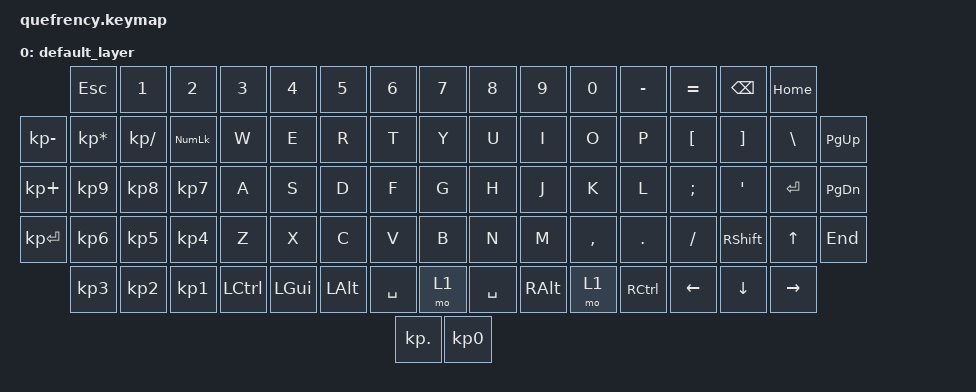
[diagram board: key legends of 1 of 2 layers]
/*
 * Copyright (c) 2020 The ZMK Contributors
 *
 * SPDX-License-Identifier: MIT
 */

#include <behaviors.dtsi>
#include <dt-bindings/zmk/bt.h>
#include <dt-bindings/zmk/keys.h>

/ {
    keymap {
        compatible = "zmk,keymap";

// ------------------------------------------------------------------------------------------------------------------------------------------
// |  NA  |  NA  | MAC1 | MAC2 | |  ESC | F1  | F2  | F3  | F4  | F5  |        | F6  | F7  | F8  | F9  | F10 | F11 | F12 | DEL |  NA |  NA  |
// | Num- | Num* | Num/ | NumL | |   ~  |  1  |  2  |  3  |  4  |  5  |        |  6  |  7  |  8  |  9  |  0  |  -  |  +  |BCKSP|  NA | HOME |
// | Num+ | Num9 | Num8 | Num7 | |  TAB |  Q  |  W  |  E  |  R  |  T  |        |  Y  |  U  |  I  |  O  |  P  |  [  |  ]  |  \  |  NA | PGUP |
// | NumE | Num6 | Num5 | Num4 | | CAPS |  A  |  S  |  D  |  F  |  G  |        |  H  |  J  |  K  |  L  |  ;  |  '  |R-ENT|  NA |  NA | PGDN |
// |  NA  | Num3 | Num2 | Num1 | |SHIFT |  Z  |  X  |  C  |  V  |  B  |        |  N  |  M  |  ,  |  .  |  /  |R-SHT|  NA |  NA | UP  |  END |
// |  NA  | Num. | Num0 |  NA  | | CTRL | WIN | ALT | SPA | MAC3| MAC4|        | SPA | MAC5| MAC6|  NA |R-ALT|R-WIN|RCTRL| LEFT| DWN | RIGHT|
// ------------------------------------------------------------------------------------------------------------------------------------------

        default_layer {
            bindings = <
                                                                                  &kp ESC   &kp N1     &kp N2   &kp N3    &kp N4 &kp N5 &kp N6 /**/     &kp N7    &kp N8   &kp N9    &kp N0    &kp MINUS &kp EQUAL &kp BSPC               &kp HOME
    &kp KP_MINUS   &kp KP_MULTIPLY &kp KP_SLASH  &kp KP_NUM                          &kp W    &kp E     &kp R  &kp T    /**/     &kp Y     &kp U    &kp I     &kp O     &kp P     &kp LBKT  &kp RBKT &kp BSLH &kp PG_UP
    &kp KP_PLUS    &kp KP_N9       &kp KP_N8     &kp KP_N7                          &kp A    &kp S    &kp D     &kp F  &kp G         /**/     &kp H     &kp J    &kp K     &kp L     &kp SEMI  &kp SQT   &kp RET                &kp PG_DN
    &kp KP_ENTER   &kp KP_N6       &kp KP_N5     &kp KP_N4                         &kp Z    &kp X    &kp C     &kp V  &kp B         /**/     &kp N     &kp M    &kp COMMA &kp DOT   &kp FSLH  &kp RSHFT &kp UP                 &kp END
                   &kp KP_N3       &kp KP_N2     &kp KP_N1                                 &kp LCTRL &kp LGUI &kp LALT &kp SPACE &mo 1                /**/     &kp SPACE &kp RALT &mo 1     &kp RCTRL &kp LEFT  &kp DOWN                         &kp RIGHT
                   &kp KP_DOT      &kp KP_N0 
            >;
        };

// ----------------------------------------------     -----------------------------------------------------
// |BT_CLR|  F1  |  F2 |  F3  |  F4 |  F5 |  F6 |     |  F7 |  F8 |  F9 | F10 | F11 | F12 |        |BT_CLR|
// |       | BT-0 | BT-1| BT-2 |     |     |       |     |     |     |     |     |     |     |     |      |
// |        |      |     |      |     |     |       |     |     |     |     |     |     |          |      |
// |         |      |     |     |      |     |       |     |     |     |     |     |         |     |      |
// |         |      |      |           |     |       |             |      |    |       |     |     |      |
// -------------------------------------------       ------------------------------------------------------

        fn_layer {
            bindings = <
    &bt BT_CLR &kp F1       &kp F2       &kp F3       &kp F4 &kp F5 &kp F6 /**/ &kp F7 &kp F8 &kp F9 &kp F10 &kp F11 &kp F12 &trans &bt BT_CLR
    &trans     &bt BT_SEL 0 &bt BT_SEL 1 &bt BT_SEL 2 &trans &trans        /**/ &trans &trans &trans &trans  &trans  &trans  &trans &trans &trans
    &trans     &trans       &trans       &trans       &trans &trans        /**/ &trans &trans &trans &trans  &trans  &trans  &trans &trans
    &trans     &trans       &trans       &trans       &trans &trans        /**/ &trans &trans &trans &trans  &trans  &trans  &trans &trans
    &trans     &trans       &trans       &trans       &trans               /**/ &trans &trans &trans &trans  &trans  &trans  &trans
            >;
        };
    };
};
